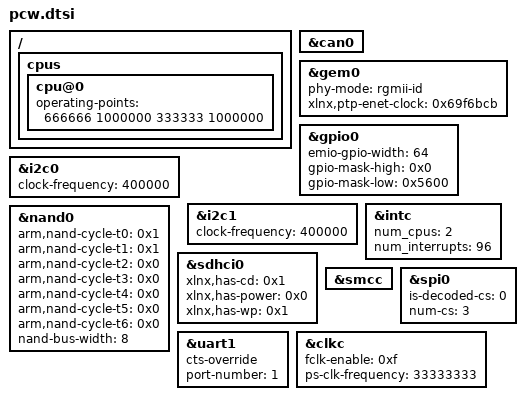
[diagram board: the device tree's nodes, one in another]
/*
 * CAUTION: This file is automatically generated by Xilinx.
 * Version: XSCT 2019.1
 * Today is: Thu Jul 17 16:31:11 2025
 */


/ {
	cpus {
		cpu@0 {
			operating-points = <666666 1000000 333333 1000000>;
		};
	};
};
&can0 {
	status = "okay";
};
&gem0 {
	phy-mode = "rgmii-id";
	status = "okay";
	xlnx,ptp-enet-clock = <0x69f6bcb>;
};
&gpio0 {
	emio-gpio-width = <64>;
	gpio-mask-high = <0x0>;
	gpio-mask-low = <0x5600>;
};
&i2c0 {
	clock-frequency = <400000>;
	status = "okay";
};
&i2c1 {
	clock-frequency = <400000>;
	status = "okay";
};
&intc {
	num_cpus = <2>;
	num_interrupts = <96>;
};
&nand0 {
	arm,nand-cycle-t0 = <0x1>;
	arm,nand-cycle-t1 = <0x1>;
	arm,nand-cycle-t2 = <0x0>;
	arm,nand-cycle-t3 = <0x0>;
	arm,nand-cycle-t4 = <0x0>;
	arm,nand-cycle-t5 = <0x0>;
	arm,nand-cycle-t6 = <0x0>;
	nand-bus-width = <8>;
	status = "okay";
};
&sdhci0 {
	status = "okay";
	xlnx,has-cd = <0x1>;
	xlnx,has-power = <0x0>;
	xlnx,has-wp = <0x1>;
};
&smcc {
	status = "okay";
};
&spi0 {
	is-decoded-cs = <0>;
	num-cs = <3>;
	status = "okay";
};
&uart1 {
	cts-override ;
	device_type = "serial";
	port-number = <1>;
	status = "okay";
};
&clkc {
	fclk-enable = <0xf>;
	ps-clk-frequency = <33333333>;
};
